# CPSW0_CPSW0 register map
Vendor: Texas Instruments
Peripheral module from a debugger description file (folder AM263).
Registers are 32-bit, read-only, reset 0x0 unless marked. A register's access mark holds for its fields unless they carry their own. Offsets are as the file gives them; lines under a group give offsets from that group; [hi:lo] are bit positions; {n}, {i} and the like mark numbered series; 'fields as' and 'values as' point back to an identical list; <NAME> marks a mode.

## CPSW0_CPSW0
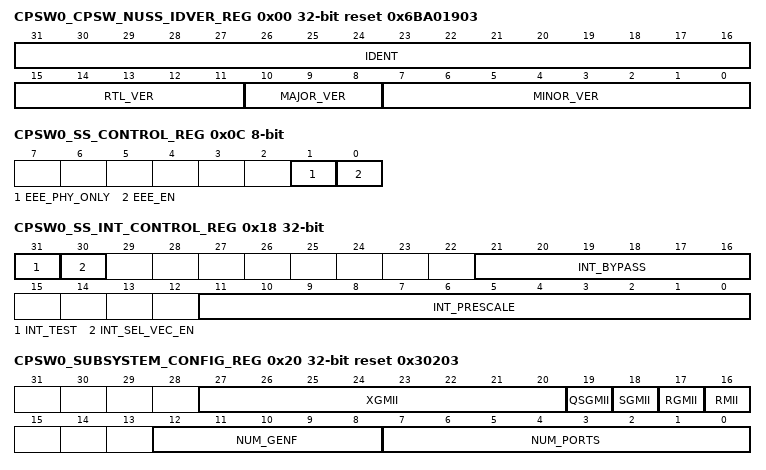
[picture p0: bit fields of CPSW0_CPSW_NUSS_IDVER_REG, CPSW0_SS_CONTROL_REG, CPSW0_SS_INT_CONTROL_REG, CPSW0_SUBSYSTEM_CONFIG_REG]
0x00 CPSW0_CPSW_NUSS_IDVER_REG reset 0x6BA01903
  [31:16] IDENT — Identification value
  [15:11] RTL_VER — RTL version value
  [10:8] MAJOR_VER — Major version value
  [7:0] MINOR_VER — Minor version value
0x04 CPSW0_SS_SYNCE_COUNT_REG rw
  [31:0] SYNCE_CNT — Sync E Count Value
0x08 CPSW0_SS_SYNCE_MUX_REG 8-bit rw
  [5:0] SYNCE_SEL — Sync E Select Value
0x0C CPSW0_SS_CONTROL_REG 8-bit rw
  [1] EEE_PHY_ONLY — Energy Efficient Enable Phy Only Mode: 0=The low power indicate state includes gating off the CPPI_GCLK to the CPSW, 1=The low power indicate state does not gate the clock to the CPSW
  [0] EEE_EN — Energy Efficient Ethernet Enable: 0=EEE is disabled, 1=EEE is enabled
0x18 CPSW0_SS_INT_CONTROL_REG rw
  [31] INT_TEST — Interrupt Test
  [30] INT_SEL_VEC_EN — Interrupt Sel Vector Enable
  [21:16] INT_BYPASS — Interrupt Bypass Value
  [11:0] INT_PRESCALE — Interrupt Prescale Value
0x1C CPSW0_SS_STATUS_REG size not given
  [0] EEE_CLKSTOP_ACK — Energy Efficient Ethernet clockstop acknowledge from CPSW
0x20 CPSW0_SUBSYSTEM_CONFIG_REG reset 0x30203
  [27:20] XGMII — The Number of XGMII Ports included in the CPSW_NUSS
  [19] QSGMII — QSGMII is included in the CPSW_NUSS
  [18] SGMII — SGMII is included in the CPSW_NUSS
  [17] RGMII — RGMII is included in the CPSW_NUSS
  [16] RMII — RMII is included in the CPSW_NUSS
  [12:8] NUM_GENF — The number of CPTS GENF outputs
  [7:0] NUM_PORTS — The total number of ports including the host port 0
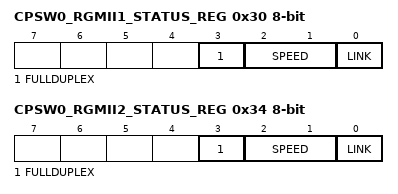
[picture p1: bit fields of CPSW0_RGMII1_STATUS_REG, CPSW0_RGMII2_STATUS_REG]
0x30 CPSW0_RGMII1_STATUS_REG 8-bit
  [3] FULLDUPLEX — Rgmii1 full dulex: 0=Half-duplex, 1=Full-duplex
  [2:1] SPEED — Rgmii1 speed: 00=10Mbps, 01=100Mbps, 10=1000Mbps, 11=reserved
  [0] LINK — Rgmii1 link indicator: 0=Link is down, 1=Link is up
0x34 CPSW0_RGMII2_STATUS_REG 8-bit
  [3] FULLDUPLEX — Rgmii2 full dulex: 0=Half-duplex, 1=Full-duplex
  [2:1] SPEED — Rgmii2 speed: 00=10Mbps, 01=100Mbps, 10=1000Mbps, 11=reserved
  [0] LINK — Rgmii2 link indicator: 0=Link is down, 1=Link is up
